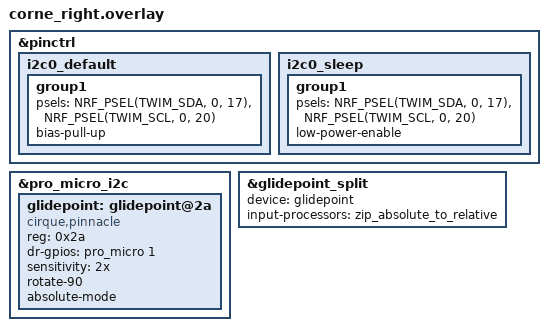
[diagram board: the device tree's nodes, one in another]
#include "./shared.dtsi"

/*#include <behaviors/input_processor_gestures.dtsi>*/
#include <behaviors/input_processor_absolute_to_relative.dtsi>

/*&i2c0 {*/
    /*compatible = "nordic,nrf-twim"; // I2C controller instead of generic*/
    /*status = "okay";*/
    /*pinctrl-0 = <&i2c0_default>;*/
    /*pinctrl-1 = <&i2c0_sleep>;*/
    /*pinctrl-names = "default", "sleep";*/
    /*clock-frequency = <I2C_BITRATE_FAST>;*/
    /*[>clock-frequency = <I2C_BITRATE_STANDARD >;<]*/

    /*[> Nodes using the bus go here <]*/
/*};*/

&pinctrl {
    i2c0_default {
        group1 {
            psels = <NRF_PSEL(TWIM_SDA, 0, 17)>,
                <NRF_PSEL(TWIM_SCL, 0, 20)>;
            bias-pull-up;
        };
    };
    i2c0_sleep: i2c0_sleep {
        group1 {
            psels = <NRF_PSEL(TWIM_SDA, 0, 17)>,
                <NRF_PSEL(TWIM_SCL, 0, 20)>;
            low-power-enable;
        };
    };
};

&pro_micro_i2c {
    status = "okay";
    glidepoint: glidepoint@2a {
        compatible = "cirque,pinnacle";
        status = "okay";
        reg = <0x2a>;
        dr-gpios = <&pro_micro 1 (GPIO_ACTIVE_HIGH)>;

        sensitivity = "2x"; // attenuation
        rotate-90;
        /*sleep;*/
        absolute-mode;
    };
};


&glidepoint_split {
    device = <&glidepoint>;
    input-processors = <
        &zip_absolute_to_relative
    >;
};

